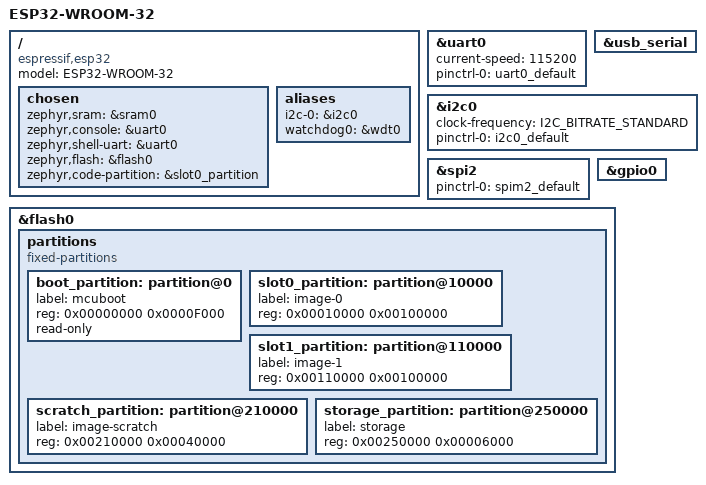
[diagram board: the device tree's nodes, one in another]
/dts-v1/;

#include <espressif/esp32/esp32.dtsi>  // Включение общего файла для ESP32
#include "esp32-wroom-32-pinctrl.dtsi"  // Включение специфического файла для ESP32-WROOM-32

/ {
    model = "ESP32-WROOM-32";
    compatible = "espressif,esp32";

    chosen {
        zephyr,sram = &sram0;
        zephyr,console = &uart0;  // Используем UART для консоли
        zephyr,shell-uart = &uart0;
        zephyr,flash = &flash0;
        zephyr,code-partition = &slot0_partition;
    };

    aliases {
        i2c-0 = &i2c0;
        watchdog0 = &wdt0;
    };
};

&uart0 {
    status = "okay";
    current-speed = <115200>;
    pinctrl-0 = <&uart0_default>;
    pinctrl-names = "default";
};

&usb_serial {
    status = "okay";
};

&i2c0 {
    status = "okay";
    clock-frequency = <I2C_BITRATE_STANDARD>;
    pinctrl-0 = <&i2c0_default>;
    pinctrl-names = "default";
};

&spi2 {
    #address-cells = <1>;
    #size-cells = <0>;
    status = "okay";
    pinctrl-0 = <&spim2_default>;
    pinctrl-names = "default";
};

&gpio0 {
    status = "okay";
};

&flash0 {
    partitions {
        compatible = "fixed-partitions";
        #address-cells = <1>;
        #size-cells = <1>;

        boot_partition: partition@0 {
            label = "mcuboot";
            reg = <0x00000000 0x0000F000>;
            read-only;
        };

        slot0_partition: partition@10000 {
            label = "image-0";
            reg = <0x00010000 0x00100000>;
        };

        slot1_partition: partition@110000 {
            label = "image-1";
            reg = <0x00110000 0x00100000>;
        };

        scratch_partition: partition@210000 {
            label = "image-scratch";
            reg = <0x00210000 0x00040000>;
        };

        storage_partition: partition@250000 {
            label = "storage";
            reg = <0x00250000 0x00006000>;
        };
    };
};
